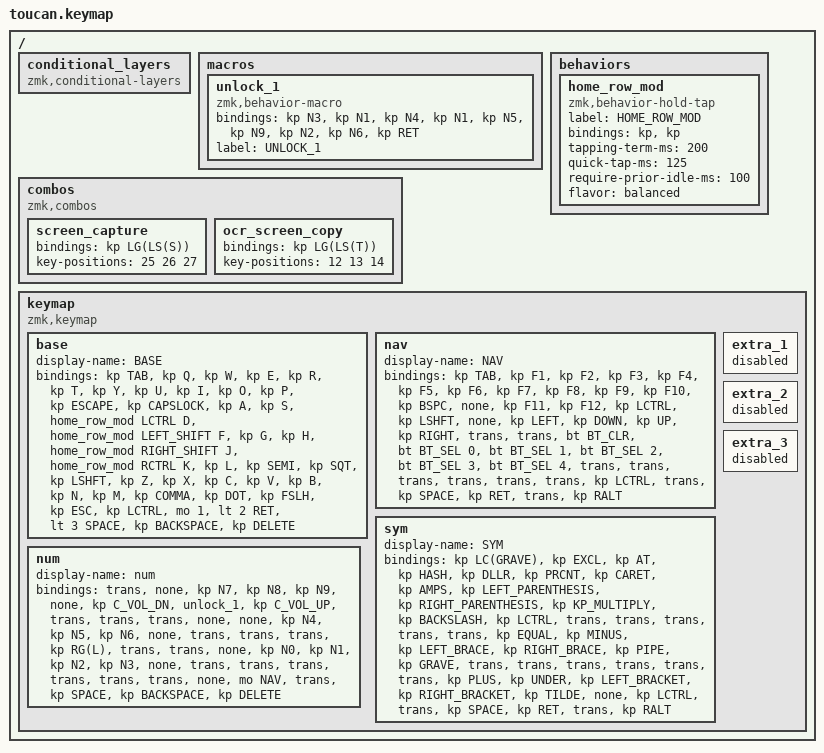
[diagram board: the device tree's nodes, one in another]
#include <behaviors.dtsi>
#include <dt-bindings/zmk/bt.h>
#include <dt-bindings/zmk/keys.h>

#define BASE 0
#define NAV  1
#define SYM  2
#define ADJ  3

/ {
    conditional_layers { compatible = "zmk,conditional-layers"; };

    macros {
        unlock_1: unlock_1 {
            compatible = "zmk,behavior-macro";
            #binding-cells = <0>;
            bindings = <&kp N3 &kp N1 &kp N4 &kp N1 &kp N5 &kp N9 &kp N2 &kp N6 &kp RET>;
            label = "UNLOCK_1";
        };
    };

    behaviors {
        home_row_mod: home_row_mod {
            compatible = "zmk,behavior-hold-tap";
            label = "HOME_ROW_MOD";
            bindings = <&kp>, <&kp>;

            #binding-cells = <2>;
            tapping-term-ms = <200>;
            quick-tap-ms = <125>;
            require-prior-idle-ms = <100>;
            flavor = "balanced";
        };
    };

    combos {
        compatible = "zmk,combos";

        screen_capture {
            bindings = <&kp LG(LS(S))>;
            key-positions = <25 26 27>;
        };

        ocr_screen_copy {
            bindings = <&kp LG(LS(T))>;
            key-positions = <12 13 14>;
        };
    };

    keymap {
        compatible = "zmk,keymap";

        base {
            display-name = "BASE";
            bindings = <
&kp TAB  &kp Q  &kp W  &kp E  &kp R  &kp T  &kp Y  &kp U  &kp I  &kp O  &kp P  &kp ESCAPE  &kp CAPSLOCK  &kp A  &kp S  &home_row_mod LCTRL D  &home_row_mod LEFT_SHIFT F  &kp G  &kp H  &home_row_mod RIGHT_SHIFT J  &home_row_mod RCTRL K  &kp L  &kp SEMI  &kp SQT  &kp LSHFT  &kp Z  &kp X  &kp C  &kp V  &kp B  &kp N  &kp M  &kp COMMA  &kp DOT  &kp FSLH  &kp ESC  &kp LCTRL  &mo 1  &lt 2 RET  &lt 3 SPACE  &kp BACKSPACE  &kp DELETE
            >;
        };

        nav {
            display-name = "NAV";
            bindings = <
&kp TAB  &kp F1  &kp F2  &kp F3  &kp F4  &kp F5  &kp F6  &kp F7  &kp F8  &kp F9  &kp F10  &kp BSPC  &none  &kp F11  &kp F12  &kp LCTRL  &kp LSHFT  &none  &kp LEFT  &kp DOWN  &kp UP  &kp RIGHT  &trans  &trans  &bt BT_CLR  &bt BT_SEL 0  &bt BT_SEL 1  &bt BT_SEL 2  &bt BT_SEL 3  &bt BT_SEL 4  &trans  &trans  &trans  &trans  &trans  &trans  &kp LCTRL  &trans  &kp SPACE  &kp RET  &trans  &kp RALT
            >;
        };

        sym {
            display-name = "SYM";
            bindings = <
&kp LC(GRAVE)  &kp EXCL  &kp AT  &kp HASH  &kp DLLR  &kp PRCNT  &kp CARET  &kp AMPS  &kp LEFT_PARENTHESIS  &kp RIGHT_PARENTHESIS  &kp KP_MULTIPLY  &kp BACKSLASH  &kp LCTRL  &trans  &trans  &trans  &trans  &trans  &kp EQUAL  &kp MINUS  &kp LEFT_BRACE  &kp RIGHT_BRACE  &kp PIPE  &kp GRAVE  &trans  &trans  &trans  &trans  &trans  &trans  &kp PLUS  &kp UNDER  &kp LEFT_BRACKET  &kp RIGHT_BRACKET  &kp TILDE  &none  &kp LCTRL  &trans  &kp SPACE  &kp RET  &trans  &kp RALT
            >;
        };

        num {
            display-name = "num";
            bindings = <
&trans  &none  &kp N7  &kp N8  &kp N9  &none  &kp C_VOL_DN  &unlock_1  &kp C_VOL_UP  &trans  &trans  &trans  &none  &none  &kp N4  &kp N5  &kp N6  &none  &trans  &trans  &trans  &kp RG(L)  &trans  &trans  &none  &kp N0  &kp N1  &kp N2  &kp N3  &none  &trans  &trans  &trans  &trans  &trans  &trans  &none  &mo NAV  &trans  &kp SPACE  &kp BACKSPACE  &kp DELETE
            >;
        };

        extra_1 { status = "reserved"; };

        extra_2 { status = "reserved"; };

        extra_3 { status = "reserved"; };
    };
};
